AUTOSAR XML (schema 4-2-2)
package /ETAS_BIP
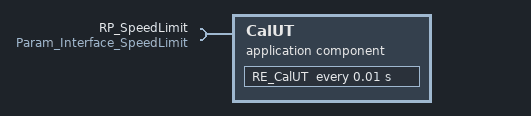
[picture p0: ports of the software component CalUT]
  application sw component type CalUT
    require port RP_SpeedLimit: required-interface=Param_Interface_SpeedLimit
    behavior IB_CalUT: data-type-mapping=DTS_MeasurementCalibration
      constant-memorys:
        parameter data prototype constParam: type=ADT_N1, init-value=constant-reference={short-label=ConstantReference_0, constant=Constant_Param_c1}
      static-memorys:
        data curveAxisInputVar: type=ADT_CurveAxis
        data mapAxisXInputVar: type=ADT_MapAxisX
        data mapAxisYInputVar: type=ADT_MapAxisY
      ar-typed-per-instance-memorys:
        data ArTypedPIM_1: type=ADT_N1  # This is ETAS BIP AUTOSAR Typed PerInstance Memory Variable example
      timing event TE_CalUT: start-on-event=RE_CalUT, period=0.01
      per-instance-parameters:
        parameter data prototype SpeedLimitUpper: category=VALUE, sw-calibration-access=READ-WRITE, type=ADT_N1, init-value=4500 rpm  # This is ETAS BIP AUTOSAR PerInstanceParameter Scalar example 2
      runnable RE_CalUT: can-be-invoked-concurrently=true
        6 x parameter access:
          PA_SpeedLimitUpper: accessed-parameter=SpeedLimitUpper
          PA_SpeedLimitLower: accessed-parameter=SpeedLimitLower
          PA_SpeedMin: accessed-parameter=RP_SpeedLimit.speedMin
          PA_SpeedMax: accessed-parameter=RP_SpeedLimit.speedMax
          PA_sharedCURVE: accessed-parameter=sharedCURVE, sw-calprm-axis-set={sw-axis-index=1, sw-axis-individual=sw-variable=curveAxisInputVar}
          PA_sharedMAP: accessed-parameter=sharedMAP, sw-calprm-axis-set=[{sw-axis-index=1, sw-axis-individual=sw-variable=mapAxisXInputVar}, {sw-axis-index=2, sw-axis-individual=sw-variable=mapAxisYInputVar}]
      shared-parameters:
        parameter data prototype SpeedLimitLower: category=VALUE, sw-calibration-access=READ-WRITE, type=ADT_N1, init-value=3000 rpm  # This is ETAS BIP AUTOSAR PerInstanceParameter Scalar example 1
        parameter data prototype sharedCURVE: category=VALUE, sw-calibration-access=READ-WRITE, type=ADT_CURVE, init-value=[-2.13 -1.5 0.34 5.2 7.8] %  # This is ETAS BIP AUTOSAR SharedParameter CURVE example
        parameter data prototype sharedMAP: category=VALUE, sw-calibration-access=READ-WRITE, type=ADT_MAP, init-value=[-3 -1 -7 2 5 7 10 12 15 22 -6 -8 -2 4 5 7 12 13 15 22] A  # This is ETAS BIP AUTOSAR SharedParameter MAP example
  data type mapping set DTS_MeasurementCalibration
    data-type-maps:
      application-data-type=ADT_N1, implementation-data-type=uint32
      application-data-type=ADT_CURVE, implementation-data-type=IDT_CURVE
      application-data-type=ADT_MAP, implementation-data-type=IDT_MAP
      application-data-type=ADT_CurveAxis, implementation-data-type=sint8
      application-data-type=ADT_MapAxisX, implementation-data-type=uint16
      application-data-type=ADT_MapAxisY, implementation-data-type=sint16
  parameter sw component type ParameterSWC: data-type-mapping=DTS_MeasurementCalibration
    provide port PP_SpeedLimit: provided-com-specs=[{init-value=1000 rpm, parameter=speedMin}, {init-value=6000 rpm, parameter=speedMax}], provided-interface=Param_Interface_SpeedLimit
package /ETAS_BIP/Pkg_ParameterInterface
  parameter interface Param_Interface_SpeedLimit
    parameter data prototype speedMin: category=VALUE, sw-calibration-access=READ-WRITE, type=ADT_N1  # This is ETAS BIP AUTOSAR Interface Scalar example 1
    parameter data prototype speedMax: category=VALUE, sw-calibration-access=READ-WRITE, type=ADT_N1  # This is ETAS BIP AUTOSAR Interface Scalar example 2
package /ETAS_BIP/MeasurementCallibration
  app type ADT_N1: category=VALUE, sw-calibration-access=READ-ONLY, compu {raw=phys*0.5; unit rpm} "LongName of N1 | Descr of N1 - Generic rotational speed data type 1", range phys 0..16383.5, sw-intended-resolution=0.5
  constant specification Constant_Param_c1: value-spec=NumericalValueSpecification_0:120
package /ETAS_BIP/ApplicationDataTypes
  5 x app type:
    ADT_CURVE:
      category=CURVE
      sw-calibration-access=READ-ONLY
      sw-calprm-axis-set={sw-axis-index=1, category=STD-AXIS, sw-axis-individual={input-variable-type=ADT_CurveAxis, compu {phys=raw} "The imported MSR Element did not contain any description. Therefore this information was inserted while generating the corresponding ARElement", unit=degC, sw-max-axis-points=10, data-constr=DataConstrC_m300p0_300p0}, sw-calibration-access=READ-ONLY, display-format=%2.1f}
      compu-method=OneToOne_Curr_A
      data-constr=DataConstrC_m300p0_300p0
      display-format=%1.1f
      sw-record-layout=IntCurve_f32_f32
    ADT_MAP:
      category=MAP
      sw-calibration-access=READ-WRITE
      sw-calprm-axis-set=[{sw-axis-index=1, category=STD-AXIS, sw-axis-individual={input-variable-type=ADT_MapAxisX, compu {phys=raw; unit V} "The imported MSR Element did not contain any description. Therefore this information was inserted while generating the corresponding ARElement", unit=V, sw-max-axis-points=10, data-constr=DataConstrC_m300p0_300p0}, sw-calibration-access=READ-WRITE, display-format=%5.1f}, {sw-axis-index=2, category=STD-AXIS, sw-axis-individual={input-variable-type=ADT_MapAxisY, compu {phys=raw; unit %} "The imported MSR Element did not contain any description. Therefore this information was inserted while generating the corresponding ARElement", unit=%, sw-max-axis-points=10, range phys -400..390, raw -400..390 "The imported MSR Element did not contain any description. Therefore this information was inserted while generating the corresponding ARElement"}, sw-calibration-access=READ-WRITE, display-format=%6.1f}]
      compu-method=OneToOne_Curr_A
      range phys -3.4e+38..3.4e+38, raw -3.4e+38..3.4e+38 "The imported MSR Element did not contain any description. Therefore this information was inserted while generating the corresponding ARElement"
      display-format=%4.1f
      sw-record-layout=IntMap_f32f32_f32
    ADT_CurveAxis: category=VALUE, sw-calibration-access=READ-WRITE
    ADT_MapAxisX: category=VALUE, sw-calibration-access=READ-ONLY
    ADT_MapAxisY: category=VALUE, sw-calibration-access=READ-ONLY
package /ETAS_BIP/ImplementationDataTypes
  impl type IDT_CURVE: category=ARRAY
    element IDT_CURVE_Type: array-size=5, array-size-semantics=FIXED-SIZE, implementation-data-type=float32
  impl type IDT_MAP: category=ARRAY
    element IDT_MAP_Type: array-size=122, array-size-semantics=FIXED-SIZE, implementation-data-type=float32
package /ETAS_BIP/CompuMethods
  compu method OneToOne_Curr_A: phys=raw; unit A  # The imported MSR Element did not contain any description. Therefore this information was inserted while generating the corresponding ARElement
package /ETAS_BIP/Units
  6 x unit:
    Rpm: display-name=rpm  # LongName of Rpm | Desc of Rpm
    NoUnit: display-name=-  # The imported MSR Element did not contain any description. Therefore this information was inserted while generating the corresponding ARElement
    Ampr: display-name=A  # The imported MSR Element did not contain any description. Therefore this information was inserted while generating the corresponding ARElement
    Perc: display-name=%  # The imported MSR Element did not contain any description. Therefore this information was inserted while generating the corresponding ARElement
    DegCgrd: display-name=degC  # The imported MSR Element did not contain any description. Therefore this information was inserted while generating the corresponding ARElement
    Volt: display-name=V  # The imported MSR Element did not contain any description. Therefore this information was inserted while generating the corresponding ARElement
package /ETAS_BIP/DataConstrs
  range DataConstrC_m300p0_300p0: phys -300..300, raw -300..300  # The imported MSR Element did not contain any description. Therefore this information was inserted while generating the corresponding ARElement
package /ETAS_BIP/SwRecordLayouts
  sw record layout IntCurve_f32_f32: sw-record-layout-group={sw-record-layout-v={short-label=N, base-type=uint32, sw-record-layout-v-axis=1, sw-record-layout-v-prop=COUNT}, sw-record-layout-group={short-label=X, category=INDEX_INCR, sw-record-layout-group-axis=1, sw-record-layout-group-index=X, sw-record-layout-group-from=1, sw-record-layout-group-to=-1, sw-record-layout-v={base-type=float32, sw-record-layout-v-axis=1, sw-record-layout-v-prop=VALUE}}, sw-record-layout-group={short-label=Val, category=COLUMN_DIR, sw-record-layout-group-axis=0, sw-record-layout-group-from=1, sw-record-layout-group-to=-1, sw-record-layout-v={base-type=float32, sw-record-layout-v-axis=0, sw-record-layout-v-prop=VALUE, sw-record-layout-v-index=X}}}
  sw record layout IntMap_f32f32_f32: sw-record-layout-group={sw-record-layout-v={short-label=Nx, base-type=uint32, sw-record-layout-v-axis=1, sw-record-layout-v-prop=COUNT}, sw-record-layout-v={short-label=Ny, base-type=uint32, sw-record-layout-v-axis=2, sw-record-layout-v-prop=COUNT}, sw-record-layout-group={short-label=X, category=INDEX_INCR, sw-record-layout-group-axis=1, sw-record-layout-group-index=X, sw-record-layout-group-from=1, sw-record-layout-group-to=-1, sw-record-layout-v={base-type=float32, sw-record-layout-v-axis=1, sw-record-layout-v-prop=VALUE}}, sw-record-layout-group={short-label=Y, category=INDEX_INCR, sw-record-layout-group-axis=2, sw-record-layout-group-index=Y, sw-record-layout-group-from=1, sw-record-layout-group-to=-1, sw-record-layout-v={base-type=float32, sw-record-layout-v-axis=2, sw-record-layout-v-prop=VALUE}}, sw-record-layout-group={short-label=Val, category=COLUMN_DIR, sw-record-layout-group-axis=1, sw-record-layout-group-index=X, sw-record-layout-group-from=1, sw-record-layout-group-to=-1, sw-record-layout-group={sw-record-layout-group-axis=2, sw-record-layout-group-index=Y, sw-record-layout-group-from=1, sw-record-layout-group-to=-1, sw-record-layout-v={base-type=float32, sw-record-layout-v-axis=0, sw-record-layout-v-prop=VALUE, sw-record-layout-v-index=X Y}}}}
